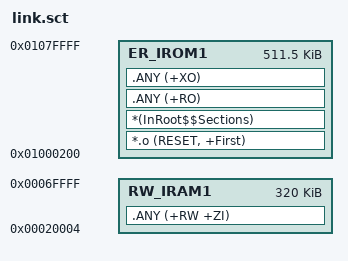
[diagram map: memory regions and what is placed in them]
; *************************************************************
; *** Scatter-Loading Description File generated by uVision ***
; *************************************************************

LR_IROM1 0x01000200 0x0007FE00  {    ; load region size_region
  ER_IROM1 0x01000200 0x0007FE00  {  ; load address = execution address
   *.o (RESET, +First)
   *(InRoot$$Sections)
   .ANY (+RO)
   .ANY (+XO)
  }
  RW_IRAM1 0x00020004 0x0004FFFC  {  ; RW data
   .ANY (+RW +ZI)
  }
}

